# Musca_S1 register map
Vendor: ARM Ltd.; Series: ARMv8-M Mainline; File version: 1.0
CPU: CM33 r0p1, little endian, MPU, no FPU, 3 interrupt priority bits, 8 SAU regions
Registers are 32-bit, read-write, reset 0x0 unless marked. A register's access mark holds for its fields unless they carry their own. Offsets are from the block's base; [hi:lo] are bit positions; {n}, {i} and the like mark numbered series.

## NSPCTRL — Non-secure Privilege Control Block
Base 0x40080000
0x90 AHBNSPPPC0 — Non-Secure Unprivileged Access AHB slave Peripheral Protection Control #0
{0xA0+4i} AHBNSPPPCEXP{i} (i=0..3) — Expansion {i} Non_Secure Unprivileged Access AHB slave Peripheral Protection Control
0xB0 APBNSPPPC0 — Non-Secure Unprivileged Access APB slave Peripheral Protection Control 0
0xB4 APBNSPPPC1 — Non-Secure Unprivileged Access APB slave Peripheral Protection Control 1
{0xC0+4i} APBNSPPPCEXP{i} (i=0..3) — Expansion {i} Non_Secure Unprivileged Access APB slave Peripheral Protection Control

## SRAM0_MPC — Memory Protection Controller 0
Base 0x50083000
Same registers: SRAM1_MPC 0x50084000, SRAM2_MPC 0x50085000, SRAM3_MPC 0x50086000, QSPI_MPC 0x50120000, CODE_SRAM_MPC 0x50130000
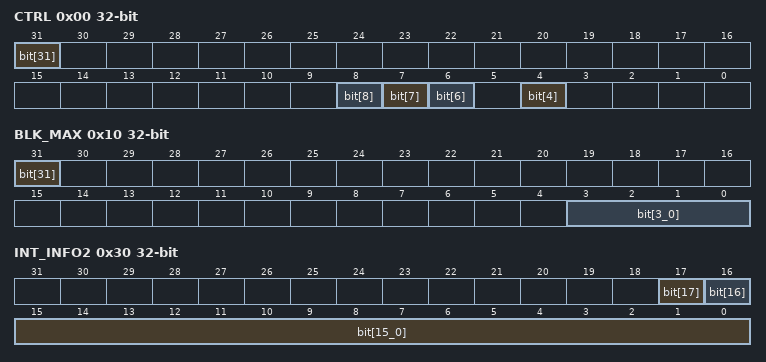
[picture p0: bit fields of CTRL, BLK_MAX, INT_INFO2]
0x00 CTRL — MPC Control Register
  [31] bit[31] — Security lockdown
  [8] bit[8] — Auto-increment
  [7] bit[7] — Data interface gating acknowledge (RO)
  [6] bit[6] — Data interface gating request
  [4] bit[4] — Security error response configuration
    0=RAZ-WI (Read-As-Zero - Writes ignored); 1=BUSERROR
0x10 BLK_MAX ro — Maximum value of block based index Register
  [31] bit[31] — Initialization in progress
  [3:0] bit[3_0] — Block size
0x14 BLK_CFG ro — Block Configuration
0x18 BLK_IDX — Index value for accessing block based look up table
0x1C BLK_LUT — Block based gating Look Up Table
0x20 INT_STAT ro — Interrupt state
  [0] bit[0] — mpc_irq triggered
0x24 INT_CLEAR wo — Interrupt clear
  [0] bit[0] — mpc_irq clear (cleared automatically)
0x28 INT_EN — Interrupt enable
  [0] bit[0] — mpc_irq enable. Bits are valid when mpc_irq triggered is set
0x2C INT_INFO1 ro — Interrupt information 1
0x30 INT_INFO2 ro — Interrupt information 2
  [17] bit[17] — cfg_ns
  [16] bit[16] — hnonsec
  [15:0] bit[15_0] — hmaster
0x34 INT_SET wo — Interrupt set. Debug purpose only
  [0] bit[0] — mpc_irq set. Debug purpose only

## SYS_PPU — SYS Power Policy Unit
Base 0x50022000
Same registers: CPU0CORE_PPU 0x50023000, CPU0DBG_PPU 0x50024000, CPU1CORE_PPU 0x50025000, CPU1DBG_PPU 0x50026000, CRYPTO_PPU 0x50027000, DBG_PPU 0x50029000, SRAM0_PPU 0x5002A000, SRAM1_PPU 0x5002B000, SRAM2_PPU 0x5002C000, SRAM3_PPU 0x5002D000
0x00 PWPR — Power Policy Register
0x04 PMER — Power Mode Emulation Register
0x08 PWSR ro — Power Status Register
0x10 DISR ro — Device Interface Input Current Status Register
0x14 MISR ro — Miscellaneous Input Current Status Register
0x18 STSR ro — Stored Status Register
0x1C UNLK — Unlock Register
0x20 PWCR — Power Configuration Register
0x24 PTCR — Power Mode Transition Configuration Register
0x30 IMR — Interrupt Mask Register
0x34 AIMR — Additional Interrupt Mask Register
0x38 ISR — Interrupt Status Register
0x3C AISR — Additional Interrupt Status Register
0x40 IESR — Input Edge Sensitivity Register
0x44 OPSR — Operating Mode Active Edge Sensitivity Register
0x50 FUNRR — Functional Retention RAM Configuration Register
0x54 FULRR — Full Retention RAM Configuration Register
0x58 MEMRR — Memory Retention RAM Configuration Register
0x160 EDTR0 — Power Mode Entry Delay Register 0
0x164 EDTR1 — Power Mode Entry Delay Register 1
0x170 DCDR0 — Device Control Delay Configuration Register 0
0x174 DCDR1 — Device Control Delay Configuration Register 1
0xFB0 IDR0 ro — PPU Identification Register 0
0xFB4 IDR1 ro — PPU Identification Register 1
0xFC8 IIDR ro — Implementation Identification Register
0xFCC AIDR ro — Architecture Identification Register

## QSPIFCTRL — QSPI Flash Controller
Base 0x4010A000
Same registers: QSPIFCTRL_Secure 0x5010A000
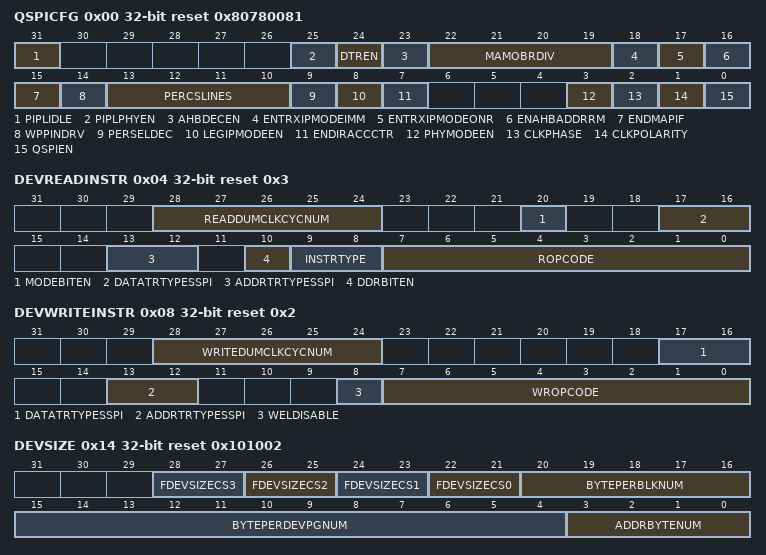
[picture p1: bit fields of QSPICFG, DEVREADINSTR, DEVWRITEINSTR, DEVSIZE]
0x00 QSPICFG reset 0x80780081 — QSPI Configuration Register
  [31] PIPLIDLE — Serial Interface and QSPI pipeline is IDLE
  [25] PIPLPHYEN — Pipeline PHY Mode enable
  [24] DTREN — Enable DTR Protocol
  [23] AHBDECEN — Enable AHB Decoder
  [22:19] MAMOBRDIV — Master mode baud rate divisor (2 to 32)
  [18] ENTRXIPMODEIMM — Enter XIP Mode immediately
  [17] ENTRXIPMODEONR — Enter XIP Mode on next READ
  [16] ENAHBADDRRM — Enable AHB Address Re-mapping
  [15] ENDMAPIF — Enable DMA Peripheral Interface
  [14] WPPINDRV — Set to drive the WP pin of Flash device
  [13:10] PERCSLINES — Peripheral chip select lines
    0bxxx0=ss0 (n_ss_out: 0b1110); 0bxx01=ss1 (n_ss_out: 0b1101); 0bx011=ss2 (n_ss_out: 0b1011); 7=ss3 (n_ss_out: 0b0111); 15=ssinactive (n_ss_out: 0b1111 (no peripheral selected))
  [9] PERSELDEC — Peripheral select decode
    0=Disabled (Only 1 of 4 selects n_ss_out is active); 1=Enabled (Allow external 4-to-16 decode)
  [8] LEGIPMODEEN — Legacy IP Mode Enable
  [7] ENDIRACCCTR — Enable Direct Access Controller
  [3] PHYMODEEN — PHY Mode enable
  [2] CLKPHASE — Clock phase, this maps to the standard SPI CPHA transfer format
  [1] CLKPOLARITY — Clock polarity outside SPI word. This maps to the standard SPI CPOL transfer format
  [0] QSPIEN — QSPI Enable
0x04 DEVREADINSTR reset 0x3 — Device Read Instruction Register
  [28:24] READDUMCLKCYCNUM — Number of Dummy Clock Cycles required by device for Read Instruction
  [20] MODEBITEN — Mode Bit Enable
  [17:16] DATATRTYPESSPI — Data Transfer Type for Standard SPI modes
  [13:12] ADDRTRTYPESSPI — Address Transfer Type for Standard SPI modes
  [10] DDRBITEN — DDR Bit Enable
  [9:8] INSTRTYPE — Instruction Type
  [7:0] ROPCODE — Read Opcode to use when not in XIP mode
0x08 DEVWRITEINSTR reset 0x2 — Device Write Instruction Configuration Register
  [28:24] WRITEDUMCLKCYCNUM — Number of Dummy Clock Cycles required by device for Write Instruction
  [17:16] DATATRTYPESSPI — Data Transfer Type for Standard SPI modes
  [13:12] ADDRTRTYPESSPI — Address Transfer Type for Standard SPI modes
  [8] WELDISABLE
  [7:0] WROPCODE — Write Opcode
0x14 DEVSIZE reset 0x101002 — Device Size Configuration Register
  [2n+22:2n+21] FDEVSIZECS{n} (n=0..3) — Size of Flash Device connected to CS[{n}] pin
  [20:16] BYTEPERBLKNUM — Number of bytes per block
  [15:4] BYTEPERDEVPGNUM — Number of bytes per device page
  [3:0] ADDRBYTENUM — Number of address bytes
0x24 REMAPADDR — Remap Address Register
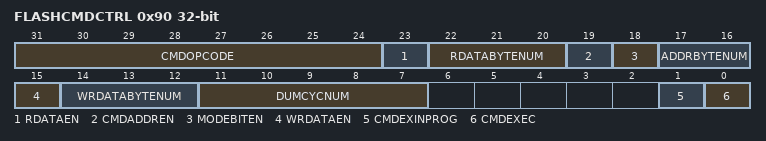
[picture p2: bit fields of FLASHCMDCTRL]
0x90 FLASHCMDCTRL — Flash Command Control Register
  [31:24] CMDOPCODE — Command Opcode
  [23] RDATAEN — Read Data Enable
  [22:20] RDATABYTENUM — Number of Read Data Bytes
  [19] CMDADDREN — Command Address Enable
  [18] MODEBITEN — Mode Bit Enable
  [17:16] ADDRBYTENUM — Number of Address Bytes
  [15] WRDATAEN — Write Data Enable
  [14:12] WRDATABYTENUM — Number of Write Data Bytes
  [11:7] DUMCYCNUM — Number of Dummy Cycles
  [1] CMDEXINPROG — Command execution in progress
  [0] CMDEXEC — Execute the command
0x94 FLASHCMDADDR — Flash Command Address Register
0xA0 FLASHCMDRDATALOW ro — Flash Command Read Data Register (Lower)
0xA4 FLASHCMDRDATAUP ro — Flash Command Read Data Register (Upper)
0xA8 FLASHCMDWRDATALOW — Flash Command Write Data Register (Lower)
0xAC FLASHCMDWRDATAUP — Flash Command Write Data Register (Upper)
